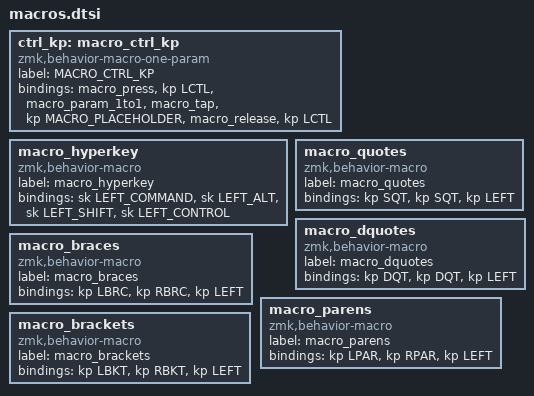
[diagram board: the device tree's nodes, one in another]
// macro_option_delete: macro_option_delete{
// compatible = "zmk,behavior-macro";
// label = "macro_option_delete";
// #binding-cells = <0>;
// bindings = <&sk LEFT_ALT>, <&kp DELETE>;
// };

#include <dt-bindings/zmk/macro.h>

ctrl_kp: macro_ctrl_kp {
    #binding-cells = <1>;
    label = "MACRO_CTRL_KP";
    compatible = "zmk,behavior-macro-one-param";
    bindings
        = <&macro_press &kp LCTL>
        , <&macro_param_1to1>
        , <&macro_tap &kp MACRO_PLACEHOLDER>
        , <&macro_release &kp LCTL>;
};


macro_hyperkey: macro_hyperkey{
	compatible = "zmk,behavior-macro";
	label = "macro_hyperkey";
	#binding-cells = <0>;
	bindings = <&sk LEFT_COMMAND>, <&sk LEFT_ALT>, <&sk LEFT_SHIFT>, <&sk LEFT_CONTROL>;
};
macro_quotes: macro_quotes{
	compatible = "zmk,behavior-macro";
	label = "macro_quotes";
	#binding-cells = <0>;
	bindings = <&kp SQT>, <&kp SQT>, <&kp LEFT>;
};
macro_dquotes: macro_dquotes{
	compatible = "zmk,behavior-macro";
	label = "macro_dquotes";
	#binding-cells = <0>;
	bindings = <&kp DQT>, <&kp DQT>, <&kp LEFT>;
};
macro_braces: macro_braces{
	compatible = "zmk,behavior-macro";
	label = "macro_braces";
	#binding-cells = <0>;
	bindings = <&kp LBRC>, <&kp RBRC>, <&kp LEFT>;
};
macro_parens: macro_parens{
	compatible = "zmk,behavior-macro";
	label = "macro_parens";
	#binding-cells = <0>;
	bindings = <&kp LPAR>, <&kp RPAR>, <&kp LEFT>;
};
macro_brackets: macro_brackets{
	compatible = "zmk,behavior-macro";
	label = "macro_brackets";
	#binding-cells = <0>;
	bindings = <&kp LBKT>, <&kp RBKT>, <&kp LEFT>;
};
